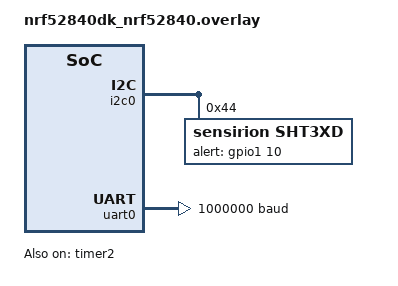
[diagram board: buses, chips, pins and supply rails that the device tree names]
/*
 * Copyright (c) 2018-2019 Peter Bigot Consulting, LLC
 * Copyright (c) 2024 Tareq Mhisen
 * SPDX-License-Identifier: Apache-2.0
 */

/ {
    chosen {
        ncs,zigbee-timer = &timer2;
        ncs,zboss-trace-uart = &uart0;
    };
};

&timer2 {
    status = "okay";
};

/* Disable unused peripherals to reduce power consumption */
&pwm0 {
    status = "disabled";
};
&pwm1 {
    status = "disabled";
};

&i2c0 {/* SDA P0.26, SCL P0.27, ALERT P1.10 */
    sht3xd@44 {
        compatible = "sensirion,sht3xd";
        reg = <0x44>;
        alert-gpios = <&gpio1 10 GPIO_ACTIVE_HIGH>;
    };
};

&uart0 {
    compatible = "nordic,nrf-uarte";
    status = "okay";
    current-speed = <1000000>;
    pinctrl-0 = <&uart0_default>;
    pinctrl-1 = <&uart0_sleep>;
    pinctrl-names = "default", "sleep";
};
